# DDR16SS0_CTLPHY_WRAP_CTL_CFG_CTLCFG register map
Vendor: Texas Instruments
Registers are 32-bit, read-write, reset 0x0 unless marked. A register's access mark holds for its fields unless they carry their own. Offsets are as the file gives them; [hi:lo] are bit positions; {n}, {i} and the like mark numbered series.

## DDR16SS0_CTLPHY_WRAP_CTL_CFG_CTLCFG (part 3 of 9)
0x244 CTLPHY_WRAP__CTL_CFG__CTLCFG_DENALI_CTL_145
  [23:0] MRR_TEMPCHK_HIGH_THRESHOLD_F1 — MRR temp check number of long counts until the high priority request is asserted. FC=1
0x248 CTLPHY_WRAP__CTL_CFG__CTLCFG_DENALI_CTL_146
  [23:0] MRR_TEMPCHK_TIMEOUT_F1 — MRR temp check number of long counts until the timeout is asserted. FC=1
0x24C CTLPHY_WRAP__CTL_CFG__CTLCFG_DENALI_CTL_147
  [23:0] MRR_TEMPCHK_NORM_THRESHOLD_F2 — MRR temp check number of long counts until the normal priority request is asserted. FC=2
0x250 CTLPHY_WRAP__CTL_CFG__CTLCFG_DENALI_CTL_148
  [23:0] MRR_TEMPCHK_HIGH_THRESHOLD_F2 — MRR temp check number of long counts until the high priority request is asserted. FC=2
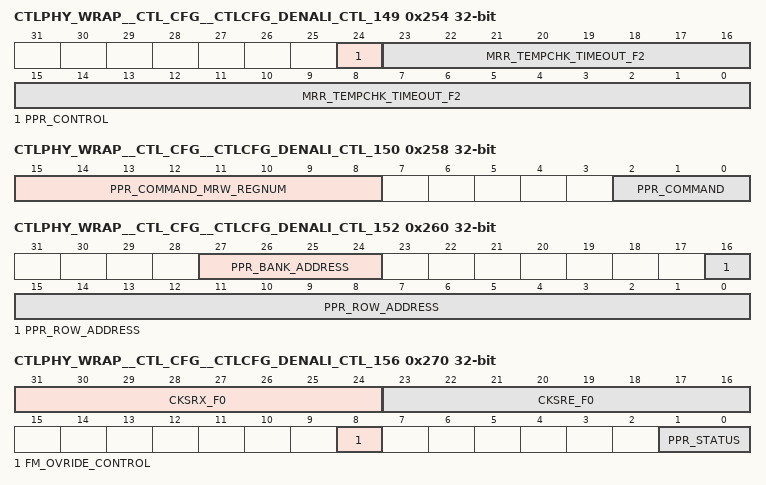
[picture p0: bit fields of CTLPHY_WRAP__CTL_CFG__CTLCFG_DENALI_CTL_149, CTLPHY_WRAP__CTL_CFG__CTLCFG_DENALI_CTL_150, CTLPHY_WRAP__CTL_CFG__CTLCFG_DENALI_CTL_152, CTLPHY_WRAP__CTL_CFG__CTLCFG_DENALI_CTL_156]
0x254 CTLPHY_WRAP__CTL_CFG__CTLCFG_DENALI_CTL_149
  [24] PPR_CONTROL — Enables the post-package repair feature. Set to 1 to enable. This parameter may only be programmed before initialization begins.
  [23:0] MRR_TEMPCHK_TIMEOUT_F2 — MRR temp check number of long counts until the timeout is asserted. FC=2
0x258 CTLPHY_WRAP__CTL_CFG__CTLCFG_DENALI_CTL_150 access per field
  [15:8] PPR_COMMAND_MRW_REGNUM rw — Specifies the mode register to be used. Clear to 0 for MRW0 or program to 4 for MRW4. All other values are reserved..
  [2:0] PPR_COMMAND wo — Specifies the type of PPR command. Program to 1 for pre-charge all, program to 2 for MRW, program to 3 for activate, or program to 5 for write. All other values are reserved. WRITE-ONLY
0x25C CTLPHY_WRAP__CTL_CFG__CTLCFG_DENALI_CTL_151
  [16:0] PPR_COMMAND_MRW_DATA — Specifies the data for the mode register write.
0x260 CTLPHY_WRAP__CTL_CFG__CTLCFG_DENALI_CTL_152
  [27:24] PPR_BANK_ADDRESS — Specifies the bank for the row to be repaired.
  [16:0] PPR_ROW_ADDRESS — Specifies the encoded row address to be repaired.
0x264 CTLPHY_WRAP__CTL_CFG__CTLCFG_DENALI_CTL_153
  [0] PPR_CS_ADDRESS — Specifies the chip select for the row to be repaired.
0x268 CTLPHY_WRAP__CTL_CFG__CTLCFG_DENALI_CTL_154
  [31:0] PPR_DATA_0 — Holds the data pattern to be written to memory for all data phases. This is specific to DDR4 memories.
0x26C CTLPHY_WRAP__CTL_CFG__CTLCFG_DENALI_CTL_155
  [31:0] PPR_DATA_1 — Holds the data pattern to be written to memory for all data phases. This is specific to DDR4 memories.
0x270 CTLPHY_WRAP__CTL_CFG__CTLCFG_DENALI_CTL_156 access per field
  [31:24] CKSRX_F0 rw — Clock stable delay on self-refresh exit. FC=0
  [23:16] CKSRE_F0 rw — Clock hold delay on self-refresh entry. FC=0
  [8] FM_OVRIDE_CONTROL rw — Enables the FM Override feature. Set to 1 to enable.
  [1:0] PPR_STATUS ro — Reports the status of the PPR operation. Bit [0] set indicates that PPR operations are now allowed and bit [1] set indicates if the last PPR command is complete. READ-ONLY
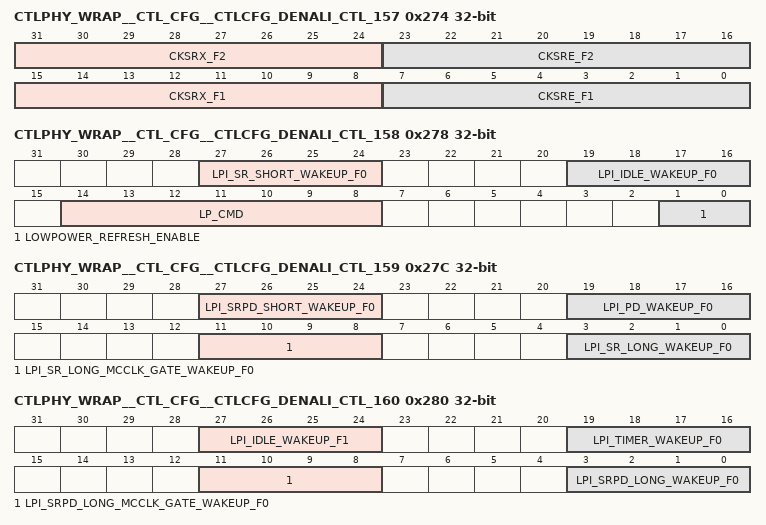
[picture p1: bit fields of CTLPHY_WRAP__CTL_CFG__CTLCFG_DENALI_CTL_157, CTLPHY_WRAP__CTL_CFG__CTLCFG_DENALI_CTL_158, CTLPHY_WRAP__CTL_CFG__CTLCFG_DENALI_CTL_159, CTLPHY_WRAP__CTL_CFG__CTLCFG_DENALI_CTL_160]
0x274 CTLPHY_WRAP__CTL_CFG__CTLCFG_DENALI_CTL_157
  [31:24] CKSRX_F2 — Clock stable delay on self-refresh exit. FC=2
  [23:16] CKSRE_F2 — Clock hold delay on self-refresh entry. FC=2
  [15:8] CKSRX_F1 — Clock stable delay on self-refresh exit. FC=1
  [7:0] CKSRE_F1 — Clock hold delay on self-refresh entry. FC=1
0x278 CTLPHY_WRAP__CTL_CFG__CTLCFG_DENALI_CTL_158 access per field
  [27:24] LPI_SR_SHORT_WAKEUP_F0 rw — Defines the DFI tLP_WAKEUP timing parameter [in DFI clocks] to be driven when LPDDR4 memory is in the self-refresh short state [with or without memory clock gating]. For LPDDR4, SR_SHORT is used to send few commands so this wakeup time must be cleared to ZERO and no LPI request needs to be asserted. FC=0
  [19:16] LPI_IDLE_WAKEUP_F0 rw — Defines the DFI tLP_CTRL_WAKEUP timing parameter [in DFI clocks] to be driven when controller is idle. FC=0
  [14:8] LP_CMD wo — Low power software command request interface. Bit [0] controls exit, bit [1] controls entry, bits [4:2] define the low power state, bit [5] controls memory clock gating, bit [6] controls controller clock gating, and bit [7] controls lock. WRITE-ONLY
  [1:0] LOWPOWER_REFRESH_ENABLE rw — Enable refreshes while in low power mode. Bit [0] controls cs0, bit [1] controls cs1, etc. Set each bit to 1 to disable.
0x27C CTLPHY_WRAP__CTL_CFG__CTLCFG_DENALI_CTL_159
  [27:24] LPI_SRPD_SHORT_WAKEUP_F0 — Defines the DFI tLP_WAKEUP timing parameter [in DFI clocks] to be driven when memory is in the self-refresh power-down short state [with or without memory clock gating]. FC=0
  [19:16] LPI_PD_WAKEUP_F0 — Defines the DFI tLP_WAKEUP timing parameter [in DFI clocks] to be driven when memory is in any of the power-down states [with or without memory clock gating]. FC=0
  [11:8] LPI_SR_LONG_MCCLK_GATE_WAKEUP_F0 — Defines the DFI tLP_WAKEUP timing parameter [in DFI clocks] to be driven when memory is in the self-refresh long with memory and controller clock gating state. FC=0
  [3:0] LPI_SR_LONG_WAKEUP_F0 — Defines the DFI tLP_WAKEUP timing parameter [in DFI clocks] to be driven when memory is in the self-refresh long state [with or without memory clock gating]. FC=0
0x280 CTLPHY_WRAP__CTL_CFG__CTLCFG_DENALI_CTL_160
  [27:24] LPI_IDLE_WAKEUP_F1 — Defines the DFI tLP_CTRL_WAKEUP timing parameter [in DFI clocks] to be driven when controller is idle. FC=1
  [19:16] LPI_TIMER_WAKEUP_F0 — Defines the DFI tLP_WAKEUP timing parameter [in DFI clocks] to be driven when the LPI timer expires. FC=0
  [11:8] LPI_SRPD_LONG_MCCLK_GATE_WAKEUP_F0 — Defines the DFI tLP_WAKEUP timing parameter [in DFI clocks] to be driven when memory is in the self-refresh power-down long with memory and controller clock gating state. FC=0
  [3:0] LPI_SRPD_LONG_WAKEUP_F0 — Defines the DFI tLP_WAKEUP timing parameter [in DFI clocks] to be driven when memory is in the self-refresh power-down long state [with or without memory clock gating]. FC=0
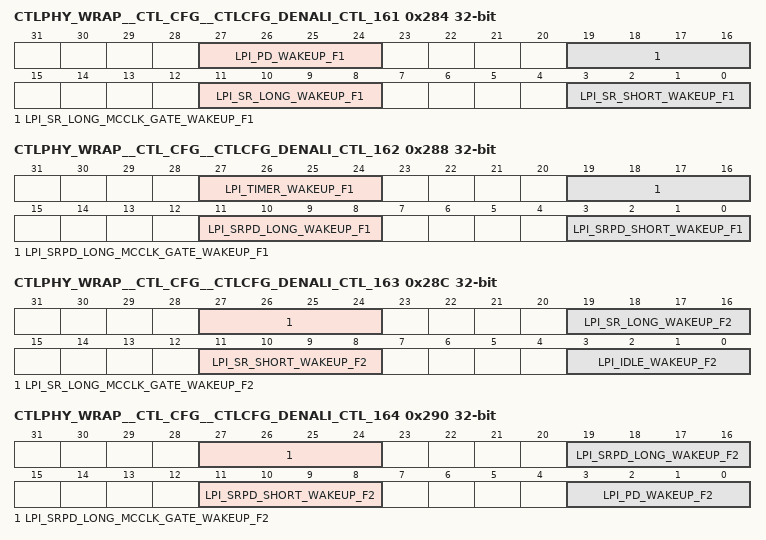
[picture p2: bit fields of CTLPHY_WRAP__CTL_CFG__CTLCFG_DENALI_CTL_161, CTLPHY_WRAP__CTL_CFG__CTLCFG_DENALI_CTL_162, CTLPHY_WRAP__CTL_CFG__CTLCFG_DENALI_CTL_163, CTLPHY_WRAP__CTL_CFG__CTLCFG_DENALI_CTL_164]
0x284 CTLPHY_WRAP__CTL_CFG__CTLCFG_DENALI_CTL_161
  [27:24] LPI_PD_WAKEUP_F1 — Defines the DFI tLP_WAKEUP timing parameter [in DFI clocks] to be driven when memory is in any of the power-down states [with or without memory clock gating]. FC=1
  [19:16] LPI_SR_LONG_MCCLK_GATE_WAKEUP_F1 — Defines the DFI tLP_WAKEUP timing parameter [in DFI clocks] to be driven when memory is in the self-refresh long with memory and controller clock gating state. FC=1
  [11:8] LPI_SR_LONG_WAKEUP_F1 — Defines the DFI tLP_WAKEUP timing parameter [in DFI clocks] to be driven when memory is in the self-refresh long state [with or without memory clock gating]. FC=1
  [3:0] LPI_SR_SHORT_WAKEUP_F1 — Defines the DFI tLP_WAKEUP timing parameter [in DFI clocks] to be driven when LPDDR4 memory is in the self-refresh short state [with or without memory clock gating]. For LPDDR4, SR_SHORT is used to send few commands so this wakeup time must be cleared to ZERO and no LPI request needs to be asserted. FC=1
0x288 CTLPHY_WRAP__CTL_CFG__CTLCFG_DENALI_CTL_162
  [27:24] LPI_TIMER_WAKEUP_F1 — Defines the DFI tLP_WAKEUP timing parameter [in DFI clocks] to be driven when the LPI timer expires. FC=1
  [19:16] LPI_SRPD_LONG_MCCLK_GATE_WAKEUP_F1 — Defines the DFI tLP_WAKEUP timing parameter [in DFI clocks] to be driven when memory is in the self-refresh power-down long with memory and controller clock gating state. FC=1
  [11:8] LPI_SRPD_LONG_WAKEUP_F1 — Defines the DFI tLP_WAKEUP timing parameter [in DFI clocks] to be driven when memory is in the self-refresh power-down long state [with or without memory clock gating]. FC=1
  [3:0] LPI_SRPD_SHORT_WAKEUP_F1 — Defines the DFI tLP_WAKEUP timing parameter [in DFI clocks] to be driven when memory is in the self-refresh power-down short state [with or without memory clock gating]. FC=1
0x28C CTLPHY_WRAP__CTL_CFG__CTLCFG_DENALI_CTL_163
  [27:24] LPI_SR_LONG_MCCLK_GATE_WAKEUP_F2 — Defines the DFI tLP_WAKEUP timing parameter [in DFI clocks] to be driven when memory is in the self-refresh long with memory and controller clock gating state. FC=2
  [19:16] LPI_SR_LONG_WAKEUP_F2 — Defines the DFI tLP_WAKEUP timing parameter [in DFI clocks] to be driven when memory is in the self-refresh long state [with or without memory clock gating]. FC=2
  [11:8] LPI_SR_SHORT_WAKEUP_F2 — Defines the DFI tLP_WAKEUP timing parameter [in DFI clocks] to be driven when LPDDR4 memory is in the self-refresh short state [with or without memory clock gating]. For LPDDR4, SR_SHORT is used to send few commands so this wakeup time must be cleared to ZERO and no LPI request needs to be asserted. FC=2
  [3:0] LPI_IDLE_WAKEUP_F2 — Defines the DFI tLP_CTRL_WAKEUP timing parameter [in DFI clocks] to be driven when controller is idle. FC=2
0x290 CTLPHY_WRAP__CTL_CFG__CTLCFG_DENALI_CTL_164
  [27:24] LPI_SRPD_LONG_MCCLK_GATE_WAKEUP_F2 — Defines the DFI tLP_WAKEUP timing parameter [in DFI clocks] to be driven when memory is in the self-refresh power-down long with memory and controller clock gating state. FC=2
  [19:16] LPI_SRPD_LONG_WAKEUP_F2 — Defines the DFI tLP_WAKEUP timing parameter [in DFI clocks] to be driven when memory is in the self-refresh power-down long state [with or without memory clock gating]. FC=2
  [11:8] LPI_SRPD_SHORT_WAKEUP_F2 — Defines the DFI tLP_WAKEUP timing parameter [in DFI clocks] to be driven when memory is in the self-refresh power-down short state [with or without memory clock gating]. FC=2
  [3:0] LPI_PD_WAKEUP_F2 — Defines the DFI tLP_WAKEUP timing parameter [in DFI clocks] to be driven when memory is in any of the power-down states [with or without memory clock gating]. FC=2
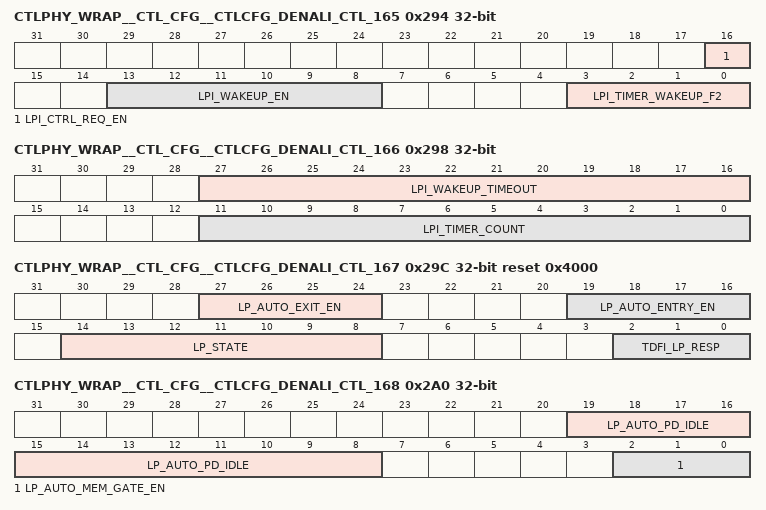
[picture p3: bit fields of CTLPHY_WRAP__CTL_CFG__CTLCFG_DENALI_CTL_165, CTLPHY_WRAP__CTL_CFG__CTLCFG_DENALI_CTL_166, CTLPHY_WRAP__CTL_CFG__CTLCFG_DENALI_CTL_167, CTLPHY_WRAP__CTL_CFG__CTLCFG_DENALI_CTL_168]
0x294 CTLPHY_WRAP__CTL_CFG__CTLCFG_DENALI_CTL_165
  [16] LPI_CTRL_REQ_EN — Enables the dfi_lpi_ctrl_req signal for the LPI. This signal is only relevant for DFI versions 3.1 and beyond. Set to 1 to enable or clear to 0 to disable.
  [13:8] LPI_WAKEUP_EN — Enables the various low power state wakeup parameters for LPI request uses. Bit [0] enables controller idle wakeup, bit [1] enables power-down wakeup, bit [2] enables either self-refresh short, self-refresh long with or without mem clk gating, either self-refresh power-down short, or self-refresh power-down long with or without mem clk gating, bit [3] enables self-refresh long with mem and ctlr clk gating or self-refresh power-down long with mem and ctlr clk gating, bit [4] enables the LPI timer expire wakeup, and bit [5] is reserved. Set each bit to 1 to enable the respective LP_WAKEUP value for the LPI request.
  [3:0] LPI_TIMER_WAKEUP_F2 — Defines the DFI tLP_WAKEUP timing parameter [in DFI clocks] to be driven when the LPI timer expires. FC=2
0x298 CTLPHY_WRAP__CTL_CFG__CTLCFG_DENALI_CTL_166
  [27:16] LPI_WAKEUP_TIMEOUT — Defines the LPI timeout time, the maximum cycles between a dfi_lp_req de-assertion and a dfi_lp_ack de-assertion. If this value is exceeded, an interrupt will occur.
  [11:0] LPI_TIMER_COUNT — Defines the LPI timer count.
0x29C CTLPHY_WRAP__CTL_CFG__CTLCFG_DENALI_CTL_167 access per field reset 0x4000
  [27:24] LP_AUTO_EXIT_EN rw — Enable auto exit from each of the low power states when a read or write command enters the command queue. Bit [0] controls power-down, bit [1] controls self-refresh long or self-refresh power-down long, bit [2] controls self-refresh long with memory and controller clock gating or self-refresh power-down long with memory and controller clock gating, and bit [3] controls self-refresh short or self-refresh power-down short. Set each bit to 1 to enable.
  [19:16] LP_AUTO_ENTRY_EN rw — Enable auto entry into each of the low power states when the associated idle timer expires. Bit [0] controls power-down, bit [1] controls self-refresh long or self-refresh power-down long, bit [2] controls self-refresh long with memory and controller clock gating or self-refresh power-down long with memory and controller clock gating, and bit [3] controls self-refresh short or self-refresh power-down short. Set each bit to 1 to enable.
  [14:8] LP_STATE ro — Low power state status parameter. Bits [5:0] indicate the current low power state and bit [6] set indicates that status bits are valid. READ-ONLY
  [2:0] TDFI_LP_RESP rw — Defines the DFI tLP_RESP timing parameter [in DFI clocks], the maximum cycles between a dfi_lp_req assertion and a dfi_lp_ack assertion.
0x2A0 CTLPHY_WRAP__CTL_CFG__CTLCFG_DENALI_CTL_168
  [19:8] LP_AUTO_PD_IDLE — Defines the idle time [in controller clocks] until the controller will automatically issue an entry into one of the power-down low power states.
  [2:0] LP_AUTO_MEM_GATE_EN — Enable memory clock gating when entering a low power state via the auto low power counters. Bit [0] controls power-down, bit [1] controls self-refresh long or self-refresh power-down long, and bit [2] controls self-refresh short or self-refresh power-down short. Set each bit to 1 to enable.
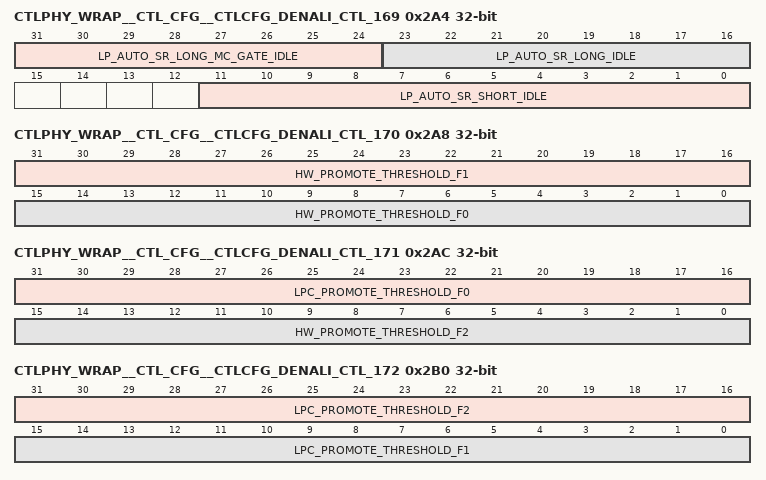
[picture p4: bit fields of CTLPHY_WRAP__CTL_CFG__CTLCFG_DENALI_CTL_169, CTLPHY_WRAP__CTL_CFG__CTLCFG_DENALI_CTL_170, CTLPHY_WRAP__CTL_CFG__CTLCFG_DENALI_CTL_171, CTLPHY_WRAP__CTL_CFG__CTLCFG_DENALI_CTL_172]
0x2A4 CTLPHY_WRAP__CTL_CFG__CTLCFG_DENALI_CTL_169
  [31:24] LP_AUTO_SR_LONG_MC_GATE_IDLE — Defines the idle time [in long counts] until the controller will automatically issue an entry into the self-refresh long with memory and controller clock gating or self-refresh power-down long with memory and controller clock gating low power states.
  [23:16] LP_AUTO_SR_LONG_IDLE — Defines the idle time [in long counts] until the controller will automatically issue an entry into the self-refresh long or self-refresh power-down long [with or without memory clock gating] low power states.
  [11:0] LP_AUTO_SR_SHORT_IDLE — Defines the idle time [in controller clocks] until the controller will automatically issue an entry into the self-refresh short or self-refresh power-down short [with or without memory clock gating] low power states.
0x2A8 CTLPHY_WRAP__CTL_CFG__CTLCFG_DENALI_CTL_170
  [31:16] HW_PROMOTE_THRESHOLD_F1 — HW interface promotion number of long counts until the high priority request is asserted. FC=1
  [15:0] HW_PROMOTE_THRESHOLD_F0 — HW interface promotion number of long counts until the high priority request is asserted. FC=0
0x2AC CTLPHY_WRAP__CTL_CFG__CTLCFG_DENALI_CTL_171
  [31:16] LPC_PROMOTE_THRESHOLD_F0 — LPC promotion number of long counts until the high priority request is asserted for frequency copy 2. Applies to SW and auto low power commands. FC=0
  [15:0] HW_PROMOTE_THRESHOLD_F2 — HW interface promotion number of long counts until the high priority request is asserted. FC=2
0x2B0 CTLPHY_WRAP__CTL_CFG__CTLCFG_DENALI_CTL_172
  [31:16] LPC_PROMOTE_THRESHOLD_F2 — LPC promotion number of long counts until the high priority request is asserted for frequency copy 2. Applies to SW and auto low power commands. FC=2
  [15:0] LPC_PROMOTE_THRESHOLD_F1 — LPC promotion number of long counts until the high priority request is asserted for frequency copy 2. Applies to SW and auto low power commands. FC=1
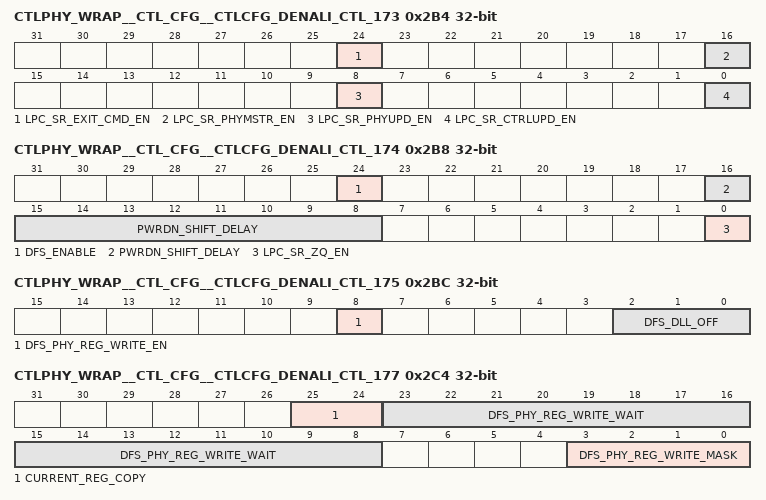
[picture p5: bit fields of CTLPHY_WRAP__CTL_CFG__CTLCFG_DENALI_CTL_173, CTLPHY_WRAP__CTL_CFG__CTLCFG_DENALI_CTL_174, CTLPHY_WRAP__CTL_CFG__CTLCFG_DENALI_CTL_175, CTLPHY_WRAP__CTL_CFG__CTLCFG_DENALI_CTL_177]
0x2B4 CTLPHY_WRAP__CTL_CFG__CTLCFG_DENALI_CTL_173
  [24] LPC_SR_EXIT_CMD_EN — Enable LPC to execute any of the commands on self-refresh exit while exiting. Set to 1 to enable.
  [16] LPC_SR_PHYMSTR_EN — Enable LPC to execute a DFI PHY Master request on a self-refresh exit sequence. Set to 1 to enable.
  [8] LPC_SR_PHYUPD_EN — Enable LPC to execute a DFI PHY update on a self-refresh exit sequence. Set to 1 to enable.
  [0] LPC_SR_CTRLUPD_EN — Enable LPC to execute a DFI control update on a self-refresh exit sequence. Set to 1 to enable.
0x2B8 CTLPHY_WRAP__CTL_CFG__CTLCFG_DENALI_CTL_174
  [24] DFS_ENABLE — Enable hardware dynamic frequency scaling. Set to 1 to enable.
  [16:8] PWRDN_SHIFT_DELAY — This parameter should be programmed to zero. Manual adjustment of inhibit_pwrdn_shift in memcd_strategy_data_delay.
  [0] LPC_SR_ZQ_EN — Enable LPC to execute a ZQ calibration on a self-refresh exit sequence. Set to 1 to enable.
0x2BC CTLPHY_WRAP__CTL_CFG__CTLCFG_DENALI_CTL_175
  [8] DFS_PHY_REG_WRITE_EN — Enable a register write to the PHY during a frequency change. Set to 1 to enable.
  [2:0] DFS_DLL_OFF — Defines if the memory DLL must be off for the associated frequency set. Bit [0] corresponds to frequency set 0, bit [1] corresponds to frequency set 1, etc. Set each bit to 1 to require DLL off.
0x2C0 CTLPHY_WRAP__CTL_CFG__CTLCFG_DENALI_CTL_176
  [31:0] DFS_PHY_REG_WRITE_ADDR — Register address which will be written during a frequency change. Must be a PHY register address.
0x2C4 CTLPHY_WRAP__CTL_CFG__CTLCFG_DENALI_CTL_177 access per field
  [25:24] CURRENT_REG_COPY ro — Indicates the current copy of timing parameters that is in use by the controller.
  [23:8] DFS_PHY_REG_WRITE_WAIT rw — Defines the number of DFI PHY clocks that the controller will wait after issuing the register write to the PHY during a frequency change.
  [3:0] DFS_PHY_REG_WRITE_MASK rw — Register mask which will be written during a frequency change.
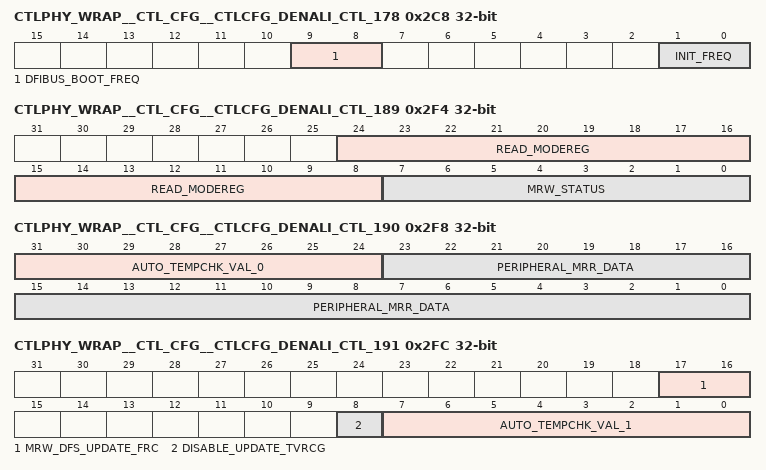
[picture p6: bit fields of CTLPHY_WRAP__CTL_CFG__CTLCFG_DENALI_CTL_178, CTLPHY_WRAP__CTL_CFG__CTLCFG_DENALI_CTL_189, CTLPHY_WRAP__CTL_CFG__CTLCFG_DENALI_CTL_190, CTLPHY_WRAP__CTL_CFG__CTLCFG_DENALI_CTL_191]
0x2C8 CTLPHY_WRAP__CTL_CFG__CTLCFG_DENALI_CTL_178
  [9:8] DFIBUS_BOOT_FREQ — Defines the DFI bus boot frequency register copy
  [1:0] INIT_FREQ — Specifies what frequency register copy will be in use by the memory after initialization completes.
{0x0+4i} CTLPHY_WRAP__CTL_CFG__CTLCFG_DENALI_CTL_{i} (i=179..181)
  [31:0] DFS_PHY_REG_WRITE_DATA_F{i-179} — Register data which will be written during a frequency change. FC={i-179}
0x2D8 CTLPHY_WRAP__CTL_CFG__CTLCFG_DENALI_CTL_182
  [23:0] TDFI_INIT_START_F0 — Defines the DFI tINIT_START timing parameter [in DFI clocks], the maximum number of cycles between a dfi_init_start assertion and a dfi_init_complete de-assertion from the PHY. FC=0
0x2DC CTLPHY_WRAP__CTL_CFG__CTLCFG_DENALI_CTL_183
  [23:0] TDFI_INIT_COMPLETE_F0 — Defines the DFI tINIT_COMPLETE timing parameter [in DFI clocks], the maximum cycles between a dfi_init_start de-assertion and a dfi_init_complete assertion from the PHY. FC=0
0x2E0 CTLPHY_WRAP__CTL_CFG__CTLCFG_DENALI_CTL_184
  [23:0] TDFI_INIT_START_F1 — Defines the DFI tINIT_START timing parameter [in DFI clocks], the maximum number of cycles between a dfi_init_start assertion and a dfi_init_complete de-assertion from the PHY. FC=1
0x2E4 CTLPHY_WRAP__CTL_CFG__CTLCFG_DENALI_CTL_185
  [23:0] TDFI_INIT_COMPLETE_F1 — Defines the DFI tINIT_COMPLETE timing parameter [in DFI clocks], the maximum cycles between a dfi_init_start de-assertion and a dfi_init_complete assertion from the PHY. FC=1
0x2E8 CTLPHY_WRAP__CTL_CFG__CTLCFG_DENALI_CTL_186
  [23:0] TDFI_INIT_START_F2 — Defines the DFI tINIT_START timing parameter [in DFI clocks], the maximum number of cycles between a dfi_init_start assertion and a dfi_init_complete de-assertion from the PHY. FC=2
0x2EC CTLPHY_WRAP__CTL_CFG__CTLCFG_DENALI_CTL_187
  [23:0] TDFI_INIT_COMPLETE_F2 — Defines the DFI tINIT_COMPLETE timing parameter [in DFI clocks], the maximum cycles between a dfi_init_start de-assertion and a dfi_init_complete assertion from the PHY. FC=2
0x2F0 CTLPHY_WRAP__CTL_CFG__CTLCFG_DENALI_CTL_188
  [26:0] WRITE_MODEREG — Write memory mode register data to the DRAMs. Bits [7:0] define the memory mode register number if bit [23] is set, bits [15:8] define the chip select if bit [24] is clear, bits [23:16] define which memory mode register/s to write, bit [24] defines whether all chip selects will be written, and bit [25] triggers the write.
0x2F4 CTLPHY_WRAP__CTL_CFG__CTLCFG_DENALI_CTL_189 access per field
  [24:8] READ_MODEREG rw — Read the specified memory mode register from specified chip when start bit set. Bits [7:0] define the memory mode register and bits [15:8] define the chip select. Set bit [16] to 1 to trigger.
  [7:0] MRW_STATUS ro — Write memory mode register status. Bit [0] set indicates a WRITE_MODEREG parameter programming error. Bit [1] set indicates a PASR error. Bit [2] is Reserved. Bit [3] set indicates a self-refresh or deep power-down error. Bit [4] set indicates that a write to MR3 or MR11 was attempted [WRITE_MODEREG bit [25] was asserted with bit [17] set, or bit [23] was asserted with bits [7:0] defining MR3 or MR11] during tZQCAL after a ZQ calibration start command. READ-ONLY
0x2F8 CTLPHY_WRAP__CTL_CFG__CTLCFG_DENALI_CTL_190 ro
  [31:24] AUTO_TEMPCHK_VAL_0 — MR4 data for all devices accessed by automatic MRR commands. Bits [3:0] correlate to the device on the lower byte, bits [7:4] correlate to the devices on the 2nd byte etc. Value indicates the OP7, OP2, OP1 and OP0 bits. READ-ONLY.
  [23:0] PERIPHERAL_MRR_DATA — Data and chip returned from memory mode register read requested by the READ_MODEREG parameter. Bits [7:0] indicate the read data and bits [15:8] indicate the chip. READ-ONLY
0x2FC CTLPHY_WRAP__CTL_CFG__CTLCFG_DENALI_CTL_191 access per field
  [17:16] MRW_DFS_UPDATE_FRC rw — Defines the frequency register set to use when doing a software MRW with WRITE_MODEREG bit [26].
  [8] DISABLE_UPDATE_TVRCG rw — Bypass changing for TVRCG during a DFS operation. Set to 1 to skip TVRCG.
  [7:0] AUTO_TEMPCHK_VAL_1 ro — MR4 data for all devices accessed by automatic MRR commands. Bits [3:0] correlate to the device on the lower byte, bits [7:4] correlate to the devices on the 2nd byte etc. Value indicates the OP7, OP2, OP1 and OP0 bits. READ-ONLY.
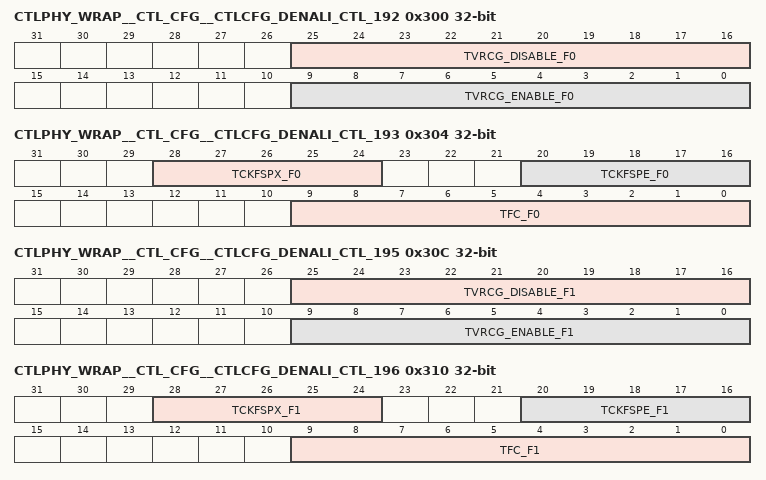
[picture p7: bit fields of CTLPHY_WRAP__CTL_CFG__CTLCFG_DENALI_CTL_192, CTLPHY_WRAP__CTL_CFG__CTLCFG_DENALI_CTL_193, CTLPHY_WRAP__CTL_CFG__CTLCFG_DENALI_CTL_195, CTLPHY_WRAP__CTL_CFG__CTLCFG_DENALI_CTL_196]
0x300 CTLPHY_WRAP__CTL_CFG__CTLCFG_DENALI_CTL_192
  [25:16] TVRCG_DISABLE_F0 — JEDEC TVRCG_DISABLE time. FC=0
  [9:0] TVRCG_ENABLE_F0 — JEDEC TVRCG_ENABLE time. FC=0
0x304 CTLPHY_WRAP__CTL_CFG__CTLCFG_DENALI_CTL_193
  [28:24] TCKFSPX_F0 — JEDEC TCKFSPX, the frequency set point switching time. FC=0
  [20:16] TCKFSPE_F0 — JEDEC TCKFSPE, the frequency set point switching time. FC=0
  [9:0] TFC_F0 — JEDEC TFC, the frequency set point switching time. FC=0
0x308 CTLPHY_WRAP__CTL_CFG__CTLCFG_DENALI_CTL_194
  [19:0] TVREF_LONG_F0 — JEDEC TVREF, design will always use the long value. FC=0
0x30C CTLPHY_WRAP__CTL_CFG__CTLCFG_DENALI_CTL_195
  [25:16] TVRCG_DISABLE_F1 — JEDEC TVRCG_DISABLE time. FC=1
  [9:0] TVRCG_ENABLE_F1 — JEDEC TVRCG_ENABLE time. FC=1
0x310 CTLPHY_WRAP__CTL_CFG__CTLCFG_DENALI_CTL_196
  [28:24] TCKFSPX_F1 — JEDEC TCKFSPX, the frequency set point switching time. FC=1
  [20:16] TCKFSPE_F1 — JEDEC TCKFSPE, the frequency set point switching time. FC=1
  [9:0] TFC_F1 — JEDEC TFC, the frequency set point switching time. FC=1
0x314 CTLPHY_WRAP__CTL_CFG__CTLCFG_DENALI_CTL_197
  [19:0] TVREF_LONG_F1 — JEDEC TVREF, design will always use the long value. FC=1
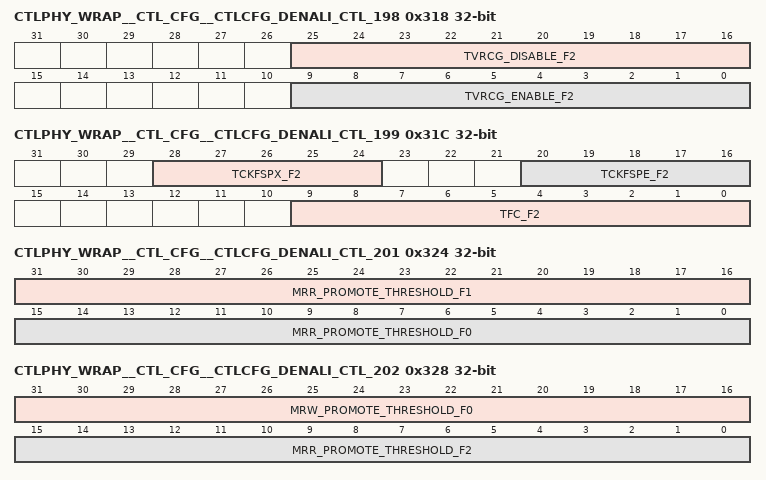
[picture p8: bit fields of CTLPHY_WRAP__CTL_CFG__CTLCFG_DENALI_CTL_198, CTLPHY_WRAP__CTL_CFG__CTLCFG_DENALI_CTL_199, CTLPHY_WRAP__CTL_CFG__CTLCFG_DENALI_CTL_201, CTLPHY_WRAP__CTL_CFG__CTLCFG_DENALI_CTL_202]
0x318 CTLPHY_WRAP__CTL_CFG__CTLCFG_DENALI_CTL_198
  [25:16] TVRCG_DISABLE_F2 — JEDEC TVRCG_DISABLE time. FC=2
  [9:0] TVRCG_ENABLE_F2 — JEDEC TVRCG_ENABLE time. FC=2
0x31C CTLPHY_WRAP__CTL_CFG__CTLCFG_DENALI_CTL_199
  [28:24] TCKFSPX_F2 — JEDEC TCKFSPX, the frequency set point switching time. FC=2
  [20:16] TCKFSPE_F2 — JEDEC TCKFSPE, the frequency set point switching time. FC=2
  [9:0] TFC_F2 — JEDEC TFC, the frequency set point switching time. FC=2
0x320 CTLPHY_WRAP__CTL_CFG__CTLCFG_DENALI_CTL_200
  [19:0] TVREF_LONG_F2 — JEDEC TVREF, design will always use the long value. FC=2
0x324 CTLPHY_WRAP__CTL_CFG__CTLCFG_DENALI_CTL_201
  [31:16] MRR_PROMOTE_THRESHOLD_F1 — MRR promotion number of long counts until the high priority request is asserted. Applies to SW MRR commands. FC=1
  [15:0] MRR_PROMOTE_THRESHOLD_F0 — MRR promotion number of long counts until the high priority request is asserted. Applies to SW MRR commands. FC=0
0x328 CTLPHY_WRAP__CTL_CFG__CTLCFG_DENALI_CTL_202
  [31:16] MRW_PROMOTE_THRESHOLD_F0 — MRW promotion number of long counts until the high priority request is asserted. Applies to SW MRW commands. FC=0
  [15:0] MRR_PROMOTE_THRESHOLD_F2 — MRR promotion number of long counts until the high priority request is asserted. Applies to SW MRR commands. FC=2
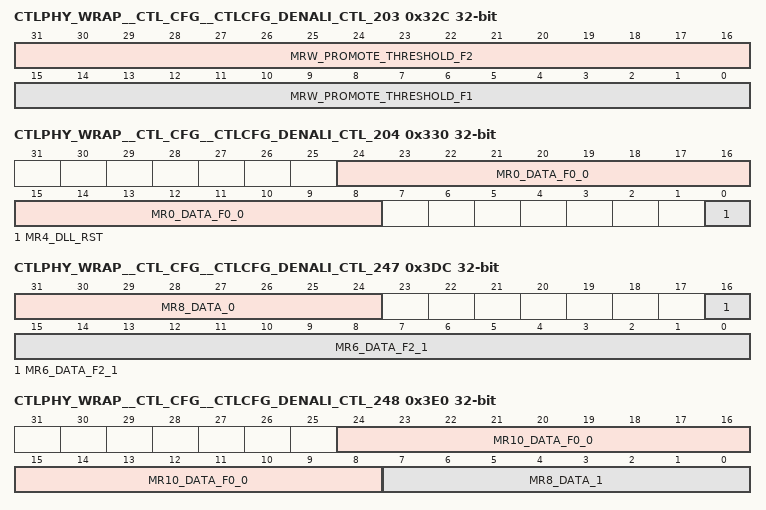
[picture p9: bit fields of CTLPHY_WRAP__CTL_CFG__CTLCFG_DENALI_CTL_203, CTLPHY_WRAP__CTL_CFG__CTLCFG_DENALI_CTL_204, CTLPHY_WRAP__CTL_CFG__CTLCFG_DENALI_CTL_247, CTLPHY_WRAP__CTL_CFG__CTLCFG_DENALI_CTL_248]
0x32C CTLPHY_WRAP__CTL_CFG__CTLCFG_DENALI_CTL_203
  [31:16] MRW_PROMOTE_THRESHOLD_F2 — MRW promotion number of long counts until the high priority request is asserted. Applies to SW MRW commands. FC=2
  [15:0] MRW_PROMOTE_THRESHOLD_F1 — MRW promotion number of long counts until the high priority request is asserted. Applies to SW MRW commands. FC=1
0x330 CTLPHY_WRAP__CTL_CFG__CTLCFG_DENALI_CTL_204
  [24:8] MR0_DATA_F0_0 — Data to program into memory mode register 0. FC=0
  [0] MR4_DLL_RST — Asserted if DRAM DLL Reset bit resides in MR4.
0x334 CTLPHY_WRAP__CTL_CFG__CTLCFG_DENALI_CTL_205
  [16:0] MR1_DATA_F0_0 — Data to program into memory mode register 1. FC=0
0x338 CTLPHY_WRAP__CTL_CFG__CTLCFG_DENALI_CTL_206
  [16:0] MR2_DATA_F0_0 — Data to program into memory mode register 2. FC=0
{0x0+4i} CTLPHY_WRAP__CTL_CFG__CTLCFG_DENALI_CTL_{i} (i=207..209)
  [16:0] MR{i-207}_DATA_F1_0 — Data to program into memory mode register {i-207}. FC=1
{0x0+4i} CTLPHY_WRAP__CTL_CFG__CTLCFG_DENALI_CTL_{i} (i=210..212)
  [16:0] MR{i-210}_DATA_F2_0 — Data to program into memory mode register {i-210}. FC=2
{0x0+4i} CTLPHY_WRAP__CTL_CFG__CTLCFG_DENALI_CTL_{i} (i=213..215)
  [16:0] MR{i-213}_DATA_F0_1 — Data to program into memory mode register {i-213}. FC=0
{0x0+4i} CTLPHY_WRAP__CTL_CFG__CTLCFG_DENALI_CTL_{i} (i=216..218)
  [16:0] MR{i-216}_DATA_F1_1 — Data to program into memory mode register {i-216}. FC=1
{0x0+4i} CTLPHY_WRAP__CTL_CFG__CTLCFG_DENALI_CTL_{i} (i=219..221)
  [16:0] MR{i-219}_DATA_F2_1 — Data to program into memory mode register {i-219}. FC=2
0x378 CTLPHY_WRAP__CTL_CFG__CTLCFG_DENALI_CTL_222
  [16:0] MRSINGLE_DATA_0 — Data to program into memory mode register single write.
0x37C CTLPHY_WRAP__CTL_CFG__CTLCFG_DENALI_CTL_223
  [16:0] MRSINGLE_DATA_1 — Data to program into memory mode register single write.
{0x0+4i} CTLPHY_WRAP__CTL_CFG__CTLCFG_DENALI_CTL_{i} (i=224..226)
  [16:0] MR3_DATA_F{i-224}_0 — Data to program into memory mode register 3. FC={i-224}
{0x0+4i} CTLPHY_WRAP__CTL_CFG__CTLCFG_DENALI_CTL_{i} (i=227..229)
  [16:0] MR3_DATA_F{i-227}_1 — Data to program into memory mode register 3. FC={i-227}
{0x0+4i} CTLPHY_WRAP__CTL_CFG__CTLCFG_DENALI_CTL_{i} (i=230..232)
  [16:0] MR4_DATA_F{i-230}_0 — Data to program into memory mode register 4. FC={i-230}
{0x0+4i} CTLPHY_WRAP__CTL_CFG__CTLCFG_DENALI_CTL_{i} (i=233..235)
  [16:0] MR4_DATA_F{i-233}_1 — Data to program into memory mode register 4. FC={i-233}
{0x0+4i} CTLPHY_WRAP__CTL_CFG__CTLCFG_DENALI_CTL_{i} (i=236..238)
  [16:0] MR5_DATA_F{i-236}_0 — Data to program into memory mode register 5. FC={i-236}
{0x0+4i} CTLPHY_WRAP__CTL_CFG__CTLCFG_DENALI_CTL_{i} (i=239..241)
  [16:0] MR5_DATA_F{i-239}_1 — Data to program into memory mode register 5. FC={i-239}
{0x0+4i} CTLPHY_WRAP__CTL_CFG__CTLCFG_DENALI_CTL_{i} (i=242..244)
  [16:0] MR6_DATA_F{i-242}_0 — Data to program into memory mode register 6. FC={i-242}
0x3D4 CTLPHY_WRAP__CTL_CFG__CTLCFG_DENALI_CTL_245
  [16:0] MR6_DATA_F0_1 — Data to program into memory mode register 6. FC=0
0x3D8 CTLPHY_WRAP__CTL_CFG__CTLCFG_DENALI_CTL_246
  [16:0] MR6_DATA_F1_1 — Data to program into memory mode register 6. FC=1
0x3DC CTLPHY_WRAP__CTL_CFG__CTLCFG_DENALI_CTL_247 access per field
  [31:24] MR8_DATA_0 ro — Data to program into memory mode register 8 for each chip select. READ-ONLY.
  [16:0] MR6_DATA_F2_1 rw — Data to program into memory mode register 6. FC=2
0x3E0 CTLPHY_WRAP__CTL_CFG__CTLCFG_DENALI_CTL_248 access per field
  [24:8] MR10_DATA_F0_0 rw — Data to program into memory mode register 10. FC=0
  [7:0] MR8_DATA_1 ro — Data to program into memory mode register 8 for each chip select. READ-ONLY.
0x3E4 CTLPHY_WRAP__CTL_CFG__CTLCFG_DENALI_CTL_249
  [16:0] MR10_DATA_F1_0 — Data to program into memory mode register 10. FC=1
0x3E8 CTLPHY_WRAP__CTL_CFG__CTLCFG_DENALI_CTL_250
  [16:0] MR10_DATA_F2_0 — Data to program into memory mode register 10. FC=2
0x3EC CTLPHY_WRAP__CTL_CFG__CTLCFG_DENALI_CTL_251
  [16:0] MR10_DATA_F0_1 — Data to program into memory mode register 10. FC=0
0x3F0 CTLPHY_WRAP__CTL_CFG__CTLCFG_DENALI_CTL_252
  [16:0] MR10_DATA_F1_1 — Data to program into memory mode register 10. FC=1
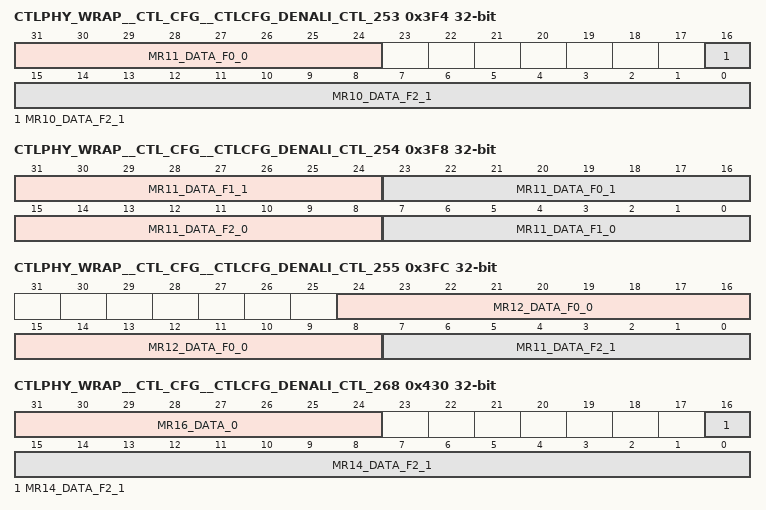
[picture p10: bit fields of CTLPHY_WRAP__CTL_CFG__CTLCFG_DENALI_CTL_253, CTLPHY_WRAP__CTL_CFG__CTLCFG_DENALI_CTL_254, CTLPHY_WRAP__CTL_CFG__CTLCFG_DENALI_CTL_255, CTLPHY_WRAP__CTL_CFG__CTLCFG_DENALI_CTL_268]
0x3F4 CTLPHY_WRAP__CTL_CFG__CTLCFG_DENALI_CTL_253
  [31:24] MR11_DATA_F0_0 — Data to program into memory mode register 11. FC=0
  [16:0] MR10_DATA_F2_1 — Data to program into memory mode register 10. FC=2
0x3F8 CTLPHY_WRAP__CTL_CFG__CTLCFG_DENALI_CTL_254
  [31:24] MR11_DATA_F1_1 — Data to program into memory mode register 11. FC=1
  [23:16] MR11_DATA_F0_1 — Data to program into memory mode register 11. FC=0
  [15:8] MR11_DATA_F2_0 — Data to program into memory mode register 11. FC=2
  [7:0] MR11_DATA_F1_0 — Data to program into memory mode register 11. FC=1
0x3FC CTLPHY_WRAP__CTL_CFG__CTLCFG_DENALI_CTL_255
  [24:8] MR12_DATA_F0_0 — Data to program into memory mode register 12. FC=0
  [7:0] MR11_DATA_F2_1 — Data to program into memory mode register 11. FC=2
0x400 CTLPHY_WRAP__CTL_CFG__CTLCFG_DENALI_CTL_256
  [16:0] MR12_DATA_F1_0 — Data to program into memory mode register 12. FC=1
0x404 CTLPHY_WRAP__CTL_CFG__CTLCFG_DENALI_CTL_257
  [16:0] MR12_DATA_F2_0 — Data to program into memory mode register 12. FC=2
{0x0+4i} CTLPHY_WRAP__CTL_CFG__CTLCFG_DENALI_CTL_{i} (i=258..260)
  [16:0] MR12_DATA_F{i-258}_1 — Data to program into memory mode register 12. FC={i-258}
0x414 CTLPHY_WRAP__CTL_CFG__CTLCFG_DENALI_CTL_261
  [16:0] MR13_DATA_0 — Data to program into memory mode register 13.
0x418 CTLPHY_WRAP__CTL_CFG__CTLCFG_DENALI_CTL_262
  [16:0] MR13_DATA_1 — Data to program into memory mode register 13.
{0x0+4i} CTLPHY_WRAP__CTL_CFG__CTLCFG_DENALI_CTL_{i} (i=263..265)
  [16:0] MR14_DATA_F{i-263}_0 — Data to program into memory mode register 14. FC={i-263}
0x428 CTLPHY_WRAP__CTL_CFG__CTLCFG_DENALI_CTL_266
  [16:0] MR14_DATA_F0_1 — Data to program into memory mode register 14. FC=0
0x42C CTLPHY_WRAP__CTL_CFG__CTLCFG_DENALI_CTL_267
  [16:0] MR14_DATA_F1_1 — Data to program into memory mode register 14. FC=1
0x430 CTLPHY_WRAP__CTL_CFG__CTLCFG_DENALI_CTL_268
  [31:24] MR16_DATA_0 — Data to program into memory mode register 16.
  [16:0] MR14_DATA_F2_1 — Data to program into memory mode register 14. FC=2
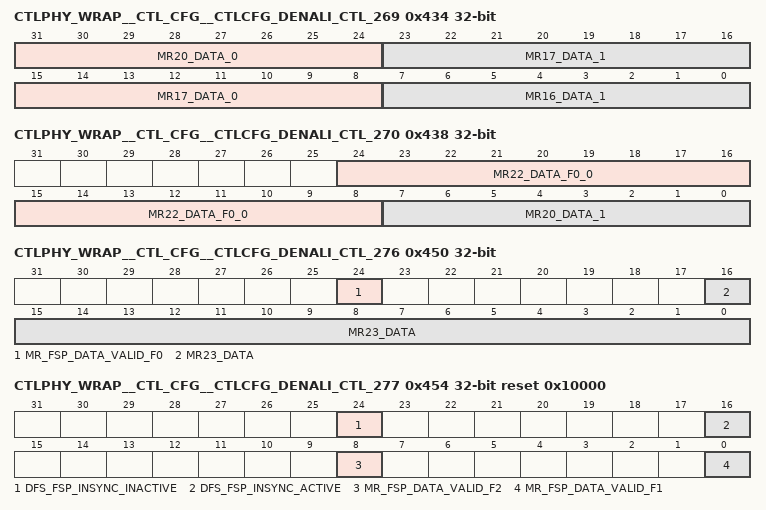
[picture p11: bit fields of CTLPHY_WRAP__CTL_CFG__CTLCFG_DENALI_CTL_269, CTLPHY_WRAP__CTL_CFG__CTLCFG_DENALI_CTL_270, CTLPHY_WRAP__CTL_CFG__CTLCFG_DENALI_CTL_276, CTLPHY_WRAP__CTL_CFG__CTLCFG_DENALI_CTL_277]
0x434 CTLPHY_WRAP__CTL_CFG__CTLCFG_DENALI_CTL_269
  [31:24] MR20_DATA_0 — Data to program into memory mode register 20.
  [23:16] MR17_DATA_1 — Data to program into memory mode register 17.
  [15:8] MR17_DATA_0 — Data to program into memory mode register 17.
  [7:0] MR16_DATA_1 — Data to program into memory mode register 16.
0x438 CTLPHY_WRAP__CTL_CFG__CTLCFG_DENALI_CTL_270
  [24:8] MR22_DATA_F0_0 — Data to program into memory mode register 22. FC=0
  [7:0] MR20_DATA_1 — Data to program into memory mode register 20.
0x43C CTLPHY_WRAP__CTL_CFG__CTLCFG_DENALI_CTL_271
  [16:0] MR22_DATA_F1_0 — Data to program into memory mode register 22. FC=1
0x440 CTLPHY_WRAP__CTL_CFG__CTLCFG_DENALI_CTL_272
  [16:0] MR22_DATA_F2_0 — Data to program into memory mode register 22. FC=2
{0x0+4i} CTLPHY_WRAP__CTL_CFG__CTLCFG_DENALI_CTL_{i} (i=273..275)
  [16:0] MR22_DATA_F{i-273}_1 — Data to program into memory mode register 22. FC={i-273}
0x450 CTLPHY_WRAP__CTL_CFG__CTLCFG_DENALI_CTL_276
  [24] MR_FSP_DATA_VALID_F0 — Indicates that, at this frequency, memory was trained and the associated data has been loaded into the MRx_DATA parameter[s]. Value of 1 means memory was trained. FC=0
  [16:0] MR23_DATA — Data to program into memory mode register 23.
0x454 CTLPHY_WRAP__CTL_CFG__CTLCFG_DENALI_CTL_277 access per field reset 0x10000
  [24] DFS_FSP_INSYNC_INACTIVE ro — When cleared, this indicates that the contents in memcd_param is new that the values in memory's MRx FSP reg and if a dfs occurs, they need to be updated. READ-ONLY
  [16] DFS_FSP_INSYNC_ACTIVE ro — When cleared, this indicates that the contents in memcd_param is new that the values in memory's MRx FSP reg and if a dfs occurs, they need to be updated. READ-ONLY
  [8] MR_FSP_DATA_VALID_F2 rw — Indicates that, at this frequency, memory was trained and the associated data has been loaded into the MRx_DATA parameter[s]. Value of 1 means memory was trained. FC=2
  [0] MR_FSP_DATA_VALID_F1 rw — Indicates that, at this frequency, memory was trained and the associated data has been loaded into the MRx_DATA parameter[s]. Value of 1 means memory was trained. FC=1
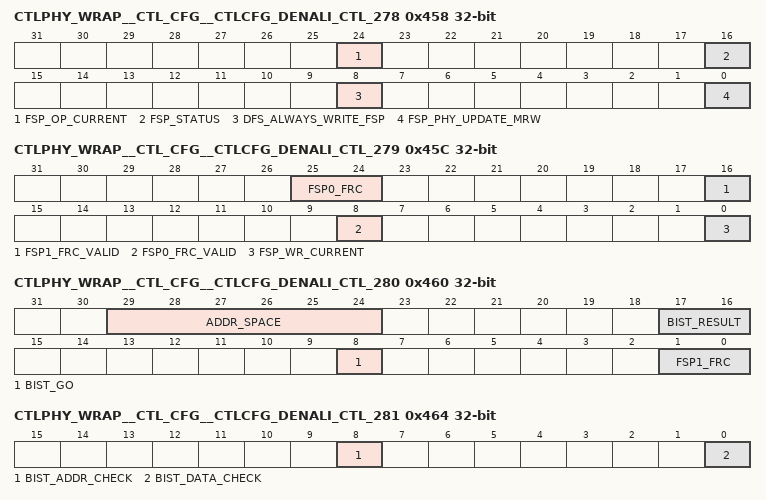
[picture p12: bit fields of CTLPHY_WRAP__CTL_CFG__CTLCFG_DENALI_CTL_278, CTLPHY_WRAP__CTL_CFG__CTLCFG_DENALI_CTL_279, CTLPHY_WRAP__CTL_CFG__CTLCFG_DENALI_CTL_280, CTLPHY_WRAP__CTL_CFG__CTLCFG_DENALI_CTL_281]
0x458 CTLPHY_WRAP__CTL_CFG__CTLCFG_DENALI_CTL_278
  [24] FSP_OP_CURRENT — Reports which FSP set the memory is currently using.
  [16] FSP_STATUS — Indicates that a DFS event caused the FSP mode registers to be updated. Value of 1 means that the FSP mode registers were changed.
  [8] DFS_ALWAYS_WRITE_FSP — Forces all FSP mode registers to be written by the controller during a DFS event. Set to 1 to force the write.
  [0] FSP_PHY_UPDATE_MRW — Identifies the logic responsible for updating MR12 and MR14 in memory. Clear to 0 for the controller, or set to 1 for the PHY or PI.
0x45C CTLPHY_WRAP__CTL_CFG__CTLCFG_DENALI_CTL_279
  [25:24] FSP0_FRC — Identifies which of the controller's frequency copy is associated with FSP0.
  [16] FSP1_FRC_VALID — Specifies whether the FSP set defined in the FSP1_FRC parameter reflects the frequency used to program the FSP1 registers.
  [8] FSP0_FRC_VALID — Specifies whether the FSP set defined in the FSP0_FRC parameter reflects the frequency used to program the FSP0 registers.
  [0] FSP_WR_CURRENT — Reports which FSP set the memory will target with write commands.
0x460 CTLPHY_WRAP__CTL_CFG__CTLCFG_DENALI_CTL_280 access per field
  [29:24] ADDR_SPACE rw — Sets the number of address bits to check during BIST operation.
  [17:16] BIST_RESULT ro — BIST operation status [pass/fail]. Bit [0] indicates data check status and bit [1] indicates address check status. Value of 1 is a passing result. READ-ONLY
  [8] BIST_GO wo — Initiate a BIST operation. Set to 1 to trigger. WRITE-ONLY
  [1:0] FSP1_FRC rw — Identifies which of the controller's frequency copy is associated with FSP1.
0x464 CTLPHY_WRAP__CTL_CFG__CTLCFG_DENALI_CTL_281
  [8] BIST_ADDR_CHECK — Enable address checking with BIST operation. Set to 1 to enable.
  [0] BIST_DATA_CHECK — Enable data checking with BIST operation. Set to 1 to enable.
0x468 CTLPHY_WRAP__CTL_CFG__CTLCFG_DENALI_CTL_282
  [31:0] BIST_START_ADDRESS_0 — Start BIST checking at this address.
0x46C CTLPHY_WRAP__CTL_CFG__CTLCFG_DENALI_CTL_283
  [0] BIST_START_ADDRESS_1 — Start BIST checking at this address.
0x470 CTLPHY_WRAP__CTL_CFG__CTLCFG_DENALI_CTL_284
  [31:0] BIST_DATA_MASK — Mask applied to data for BIST error checking. Bit [0] controls memory data path bit [0], bit [1] controls memory data path bit [1], etc. Set each bit to 1 to mask.
0x474 CTLPHY_WRAP__CTL_CFG__CTLCFG_DENALI_CTL_285
  [2:0] BIST_TEST_MODE — Sets the BIST test mode. Value of 0 specifies standard BIST operation, value of 1 specifies a reduced BIST operation, value of 2 specifies a self-refresh retention test, value of 3 specifies an idle retention test, and value of 4 specifies memory initalization function. All other values are reserved.
0x478 CTLPHY_WRAP__CTL_CFG__CTLCFG_DENALI_CTL_286
  [31:0] BIST_DATA_PATTERN_0 — Data pattern to be used when the BIST_TEST_MODE parameter is programmed to 1, 2, 3 or 4. Only data corresponding to active portion of core word will be used while inactive portion will be ignored.
0x47C CTLPHY_WRAP__CTL_CFG__CTLCFG_DENALI_CTL_287
  [31:0] BIST_DATA_PATTERN_1 — Data pattern to be used when the BIST_TEST_MODE parameter is programmed to 1, 2, 3 or 4. Only data corresponding to active portion of core word will be used while inactive portion will be ignored.
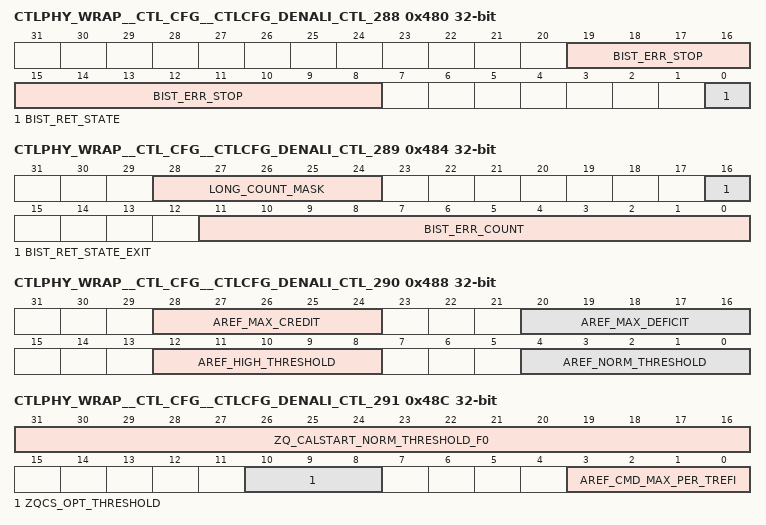
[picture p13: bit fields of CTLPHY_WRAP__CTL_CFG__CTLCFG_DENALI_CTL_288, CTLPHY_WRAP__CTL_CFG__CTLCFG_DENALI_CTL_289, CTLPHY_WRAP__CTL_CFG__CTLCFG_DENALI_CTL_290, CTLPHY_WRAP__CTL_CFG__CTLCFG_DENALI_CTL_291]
0x480 CTLPHY_WRAP__CTL_CFG__CTLCFG_DENALI_CTL_288 access per field
  [19:8] BIST_ERR_STOP rw — Defines the maximum number of error occurrences allowed prior to quitting when the BIST_TEST_MODE parameter is programmed to 1, 2 or 3. A value of 0 will allow the test to run to completion.
  [0] BIST_RET_STATE ro — Indicates if BIST is in a retention wait state, used when the BIST_TEST_MODE parameter is programmed to 2 or 3. Value of 1 indicates BIST is waiting. READ-ONLY
0x484 CTLPHY_WRAP__CTL_CFG__CTLCFG_DENALI_CTL_289 access per field
  [28:24] LONG_COUNT_MASK rw — Reduces the length of the long counter from 1024 cycles. The only supported values are 0x00 [1024 cycles], 0x10 [512 clocks], 0x18 [256 clocks], 0x1C [128 clocks], 0x1E [64 clocks] and 0x1F [32 clocks].
  [16] BIST_RET_STATE_EXIT wo — Exit self-refresh or idle retention state, used when the BIST_TEST_MODE parameter is programmed to 2 or 3. Set to 1 to trigger. WRITE-ONLY
  [11:0] BIST_ERR_COUNT ro — Indicates the number of BIST errors found when the BIST_TEST_MODE parameter is programmed to 1, 2 or 3. READ-ONLY
0x488 CTLPHY_WRAP__CTL_CFG__CTLCFG_DENALI_CTL_290
  [28:24] AREF_MAX_CREDIT — AREF number of posted refreshes until the maximum number of refresh credits has been reached.
  [20:16] AREF_MAX_DEFICIT — AREF number of pending refreshes until the maximum number of refreshes has been exceeded.
  [12:8] AREF_HIGH_THRESHOLD — AREF number of pending refreshes until the high priority request is asserted.
  [4:0] AREF_NORM_THRESHOLD — AREF number of pending refreshes until the normal priority request is asserted.
0x48C CTLPHY_WRAP__CTL_CFG__CTLCFG_DENALI_CTL_291
  [31:16] ZQ_CALSTART_NORM_THRESHOLD_F0 — ZQ START number of long counts until the normal priority request is asserted. This value should be scaled based on the number of ranks [chip selects] the controller handles. The more chip selects there are, the more rotations there are to go through, and the smaller this threshold should be. FC=0
  [10:8] ZQCS_OPT_THRESHOLD — Number of clocks before ZQCS expires when the ZQ task will deassert its request for optimal command to command turn-around timing.
  [3:0] AREF_CMD_MAX_PER_TREFI — Sets the maximum number of auto-refreshes that will be executed in a TREFI period - both normal and high priority. This does not prevent refreshes generated by sub-task requests such as a self-refresh exit and enter.
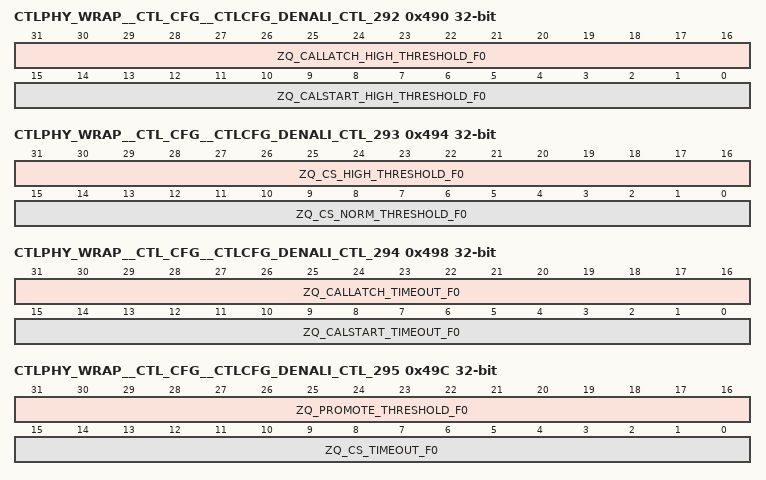
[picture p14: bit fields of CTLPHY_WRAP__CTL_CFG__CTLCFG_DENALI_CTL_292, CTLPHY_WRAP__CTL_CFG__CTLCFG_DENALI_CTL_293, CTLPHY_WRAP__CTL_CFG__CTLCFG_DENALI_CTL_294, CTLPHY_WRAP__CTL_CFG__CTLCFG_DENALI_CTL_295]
0x490 CTLPHY_WRAP__CTL_CFG__CTLCFG_DENALI_CTL_292
  [31:16] ZQ_CALLATCH_HIGH_THRESHOLD_F0 — ZQ LATCH number of long counts until the high priority request is asserted. FC=0
  [15:0] ZQ_CALSTART_HIGH_THRESHOLD_F0 — ZQ START number of long counts until the high priority request is asserted. FC=0
0x494 CTLPHY_WRAP__CTL_CFG__CTLCFG_DENALI_CTL_293
  [31:16] ZQ_CS_HIGH_THRESHOLD_F0 — ZQ CS number of long counts until the high priority request is asserted. FC=0
  [15:0] ZQ_CS_NORM_THRESHOLD_F0 — ZQ CS number of long counts until the normal priority request is asserted. FC=0
0x498 CTLPHY_WRAP__CTL_CFG__CTLCFG_DENALI_CTL_294
  [31:16] ZQ_CALLATCH_TIMEOUT_F0 — ZQ LATCH number of long counts until the timeout is asserted. FC=0
  [15:0] ZQ_CALSTART_TIMEOUT_F0 — ZQ START number of long counts until the timeout is asserted. FC=0
0x49C CTLPHY_WRAP__CTL_CFG__CTLCFG_DENALI_CTL_295
  [31:16] ZQ_PROMOTE_THRESHOLD_F0 — ZQ SW promotion number of long counts until the high priority request is asserted. FC=0
  [15:0] ZQ_CS_TIMEOUT_F0 — ZQ CS number of long counts until the timeout is asserted. FC=0
0x4A0 CTLPHY_WRAP__CTL_CFG__CTLCFG_DENALI_CTL_296
  [31:16] ZQ_CALSTART_HIGH_THRESHOLD_F1 — ZQ START number of long counts until the high priority request is asserted. FC=1
  [15:0] ZQ_CALSTART_NORM_THRESHOLD_F1 — ZQ START number of long counts until the normal priority request is asserted. This value should be scaled based on the number of ranks [chip selects] the controller handles. The more chip selects there are, the more rotations there are to go through, and the smaller this threshold should be. FC=1
0x4A4 CTLPHY_WRAP__CTL_CFG__CTLCFG_DENALI_CTL_297
  [31:16] ZQ_CS_NORM_THRESHOLD_F1 — ZQ CS number of long counts until the normal priority request is asserted. FC=1
  [15:0] ZQ_CALLATCH_HIGH_THRESHOLD_F1 — ZQ LATCH number of long counts until the high priority request is asserted. FC=1
0x4A8 CTLPHY_WRAP__CTL_CFG__CTLCFG_DENALI_CTL_298
  [31:16] ZQ_CALSTART_TIMEOUT_F1 — ZQ START number of long counts until the timeout is asserted. FC=1
  [15:0] ZQ_CS_HIGH_THRESHOLD_F1 — ZQ CS number of long counts until the high priority request is asserted. FC=1
0x4AC CTLPHY_WRAP__CTL_CFG__CTLCFG_DENALI_CTL_299
  [31:16] ZQ_CS_TIMEOUT_F1 — ZQ CS number of long counts until the timeout is asserted. FC=1
  [15:0] ZQ_CALLATCH_TIMEOUT_F1 — ZQ LATCH number of long counts until the timeout is asserted. FC=1
0x4B0 CTLPHY_WRAP__CTL_CFG__CTLCFG_DENALI_CTL_300
  [31:16] ZQ_CALSTART_NORM_THRESHOLD_F2 — ZQ START number of long counts until the normal priority request is asserted. This value should be scaled based on the number of ranks [chip selects] the controller handles. The more chip selects there are, the more rotations there are to go through, and the smaller this threshold should be. FC=2
  [15:0] ZQ_PROMOTE_THRESHOLD_F1 — ZQ SW promotion number of long counts until the high priority request is asserted. FC=1
0x4B4 CTLPHY_WRAP__CTL_CFG__CTLCFG_DENALI_CTL_301
  [31:16] ZQ_CALLATCH_HIGH_THRESHOLD_F2 — ZQ LATCH number of long counts until the high priority request is asserted. FC=2
  [15:0] ZQ_CALSTART_HIGH_THRESHOLD_F2 — ZQ START number of long counts until the high priority request is asserted. FC=2
0x4B8 CTLPHY_WRAP__CTL_CFG__CTLCFG_DENALI_CTL_302
  [31:16] ZQ_CS_HIGH_THRESHOLD_F2 — ZQ CS number of long counts until the high priority request is asserted. FC=2
  [15:0] ZQ_CS_NORM_THRESHOLD_F2 — ZQ CS number of long counts until the normal priority request is asserted. FC=2
